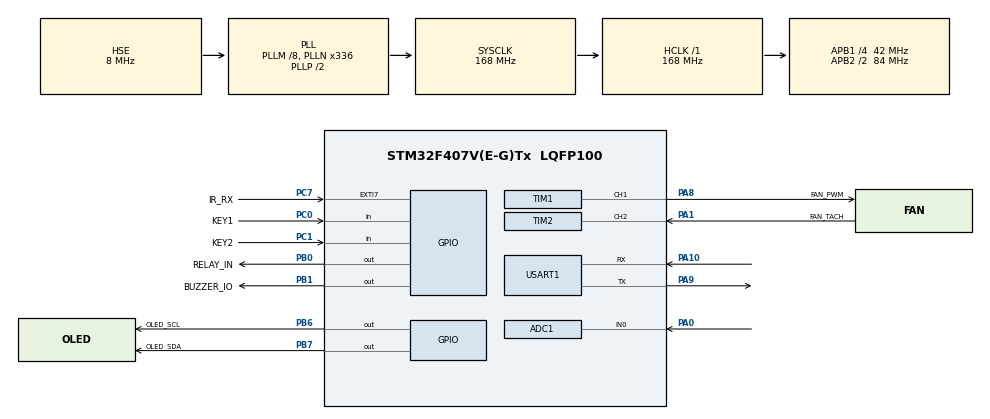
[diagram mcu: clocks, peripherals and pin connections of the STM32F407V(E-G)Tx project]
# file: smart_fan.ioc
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ADC1.Channel-0\#ChannelRegularConversion=ADC_CHANNEL_0
ADC1.NbrOfConversionFlag=1
ADC1.Rank-0\#ChannelRegularConversion=1
ADC1.SamplingTime-0\#ChannelRegularConversion=ADC_SAMPLETIME_480CYCLES
ADC1.master=1
Mcu.Family=STM32F4
Mcu.Name=STM32F407V(E-G)Tx
Mcu.Package=LQFP100
NVIC.EXTI9_5_IRQn=true\:4\:0\:false\:false\:true\:true\:true\:true
NVIC.PriorityGroup=NVIC_PRIORITYGROUP_4
NVIC.TIM2_IRQn=true\:3\:0\:false\:false\:true\:true\:true\:true
NVIC.USART1_IRQn=true\:2\:0\:false\:false\:true\:true\:true\:true
PA0-WKUP.Signal=ADCx_IN0
PA1.GPIO_Label=FAN_TACH
PA1.GPIO_PuPd=GPIO_PULLUP
PA1.GPIO_Speed=GPIO_SPEED_FREQ_LOW
PA1.Signal=S_TIM2_CH2
PA10.Mode=Asynchronous
PA10.Signal=USART1_RX
PA13.Signal=SYS_JTMS-SWDIO
PA14.Signal=SYS_JTCK-SWCLK
PA8.GPIO_Label=FAN_PWM
PA8.GPIO_ModeDefaultPP=GPIO_MODE_AF_OD
PA8.GPIO_PuPd=GPIO_NOPULL
PA8.GPIO_Speed=GPIO_SPEED_FREQ_LOW
PA8.Signal=S_TIM1_CH1
PA9.Mode=Asynchronous
PA9.Signal=USART1_TX
PB0.GPIO_Label=RELAY_IN
PB0.GPIO_ModeDefaultOutputPP=GPIO_MODE_OUTPUT_PP
PB0.GPIO_PuPd=GPIO_NOPULL
PB0.GPIO_Speed=GPIO_SPEED_FREQ_LOW
PB0.PinState=GPIO_PIN_RESET
PB0.Signal=GPIO_Output
PB1.GPIO_Label=BUZZER_IO
PB1.GPIO_ModeDefaultOutputPP=GPIO_MODE_OUTPUT_PP
PB1.GPIO_PuPd=GPIO_NOPULL
PB1.GPIO_Speed=GPIO_SPEED_FREQ_LOW
PB1.PinState=GPIO_PIN_SET
PB1.Signal=GPIO_Output
PB6.GPIO_Label=OLED_SCL
PB6.GPIO_ModeDefaultOutputPP=GPIO_MODE_OUTPUT_OD
PB6.GPIO_PuPd=GPIO_PULLUP
PB6.GPIO_Speed=GPIO_SPEED_FREQ_HIGH
PB6.Signal=GPIO_Output
PB7.GPIO_Label=OLED_SDA
PB7.GPIO_ModeDefaultOutputPP=GPIO_MODE_OUTPUT_OD
PB7.GPIO_PuPd=GPIO_PULLUP
PB7.GPIO_Speed=GPIO_SPEED_FREQ_HIGH
PB7.Signal=GPIO_Output
PC0.GPIO_Label=KEY1
PC0.GPIO_PuPd=GPIO_PULLUP
PC0.Signal=GPIO_Input
PC1.GPIO_Label=KEY2
PC1.GPIO_PuPd=GPIO_PULLUP
PC1.Signal=GPIO_Input
PC7.GPIO_Label=IR_RX
PC7.GPIO_ModeDefaultEXTI=GPIO_MODE_IT_RISING_FALLING
PC7.GPIO_PuPd=GPIO_PULLUP
PC7.Signal=GPXTI7
PH0-OSC_IN.Mode=HSE-External-Oscillator
PH0-OSC_IN.Signal=RCC_OSC_IN
PH1-OSC_OUT.Mode=HSE-External-Oscillator
PH1-OSC_OUT.Signal=RCC_OSC_OUT
ProjectManager.HeapSize=0x200
ProjectManager.StackSize=0x400
ProjectManager.TargetToolchain=CMake
RCC.48MHZClocksFreq_Value=48000000
RCC.AHBFreq_Value=168000000
RCC.APB1CLKDivider=RCC_HCLK_DIV4
RCC.APB1Freq_Value=42000000
RCC.APB1TimFreq_Value=84000000
RCC.APB2CLKDivider=RCC_HCLK_DIV2
RCC.APB2Freq_Value=84000000
RCC.APB2TimFreq_Value=168000000
RCC.CortexFreq_Value=168000000
RCC.HCLKFreq_Value=168000000
RCC.HSE_VALUE=8000000
RCC.HSI_VALUE=16000000
RCC.LSE_VALUE=32768
RCC.PLLM=8
RCC.PLLN=336
RCC.PLLQ=7
RCC.PLLSourceVirtual=RCC_PLLSOURCE_HSE
RCC.SYSCLKFreq_VALUE=168000000
RCC.SYSCLKSource=RCC_SYSCLKSOURCE_PLLCLK
RCC.VCOOutputFreq_Value=336000000
SH.ADCx_IN0.0=ADC1_IN0,IN0
SH.S_TIM1_CH1.0=TIM1_CH1,PWM Generation1 CH1
SH.S_TIM2_CH2.0=TIM2_CH2,Input_Capture2_from_TI2
TIM1.Channel-PWM\ Generation1\ CH1=TIM_CHANNEL_1
TIM1.Period=6719
TIM2.Channel-Input_Capture2_from_TI2=TIM_CHANNEL_2
TIM2.Prescaler=83
USART1.VirtualMode=VM_ASYNC
board=custom

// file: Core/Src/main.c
/* USER CODE BEGIN Header */
/**
  ******************************************************************************
  * @file           : main.c
  * @brief          : Main program body
  ******************************************************************************
  * @attention
  *
  * Copyright (c) 2026 STMicroelectronics.
  * All rights reserved.
  *
  * This software is licensed under terms that can be found in the LICENSE file
  * in the root directory of this software component.
  * If no LICENSE file comes with this software, it is provided AS-IS.
  *
  ******************************************************************************
  */
/* USER CODE END Header */
#include "main.h"

/* USER CODE BEGIN Includes */
#include "app/app_main.h"
/* USER CODE END Includes */

ADC_HandleTypeDef hadc1;

TIM_HandleTypeDef htim1;
TIM_HandleTypeDef htim2;

UART_HandleTypeDef huart1;

void SystemClock_Config(void);
static void MX_GPIO_Init(void);
static void MX_USART1_UART_Init(void);
static void MX_ADC1_Init(void);
static void MX_TIM1_Init(void);
static void MX_TIM2_Init(void);

int main(void)
{

  /* MCU Configuration--------------------------------------------------------*/

  /* Reset of all peripherals, Initializes the Flash interface and the Systick. */
  HAL_Init();

  /* Configure the system clock */
  SystemClock_Config();

  /* Initialize all configured peripherals */
  MX_GPIO_Init();
  MX_USART1_UART_Init();
  MX_ADC1_Init();
  MX_TIM1_Init();
  MX_TIM2_Init();
  /* USER CODE BEGIN 2 */
  if (app_main_init() != ERR_OK)
  {
    Error_Handler();
  }
  /* USER CODE END 2 */

  /* Infinite loop */
  /* USER CODE BEGIN WHILE */
  while (1)
  {
    app_main_run();   /* 正常情况不会返回 */
    /* USER CODE END WHILE */

  }
}

void SystemClock_Config(void)
{
  RCC_OscInitTypeDef RCC_OscInitStruct = {0};
  RCC_ClkInitTypeDef RCC_ClkInitStruct = {0};

  /** Configure the main internal regulator output voltage
  */
  __HAL_RCC_PWR_CLK_ENABLE();
  __HAL_PWR_VOLTAGESCALING_CONFIG(PWR_REGULATOR_VOLTAGE_SCALE1);

  /** Initializes the RCC Oscillators according to the specified parameters
  * in the RCC_OscInitTypeDef structure.
  */
  RCC_OscInitStruct.OscillatorType = RCC_OSCILLATORTYPE_HSE;
  RCC_OscInitStruct.HSEState = RCC_HSE_ON;
  RCC_OscInitStruct.PLL.PLLState = RCC_PLL_ON;
  RCC_OscInitStruct.PLL.PLLSource = RCC_PLLSOURCE_HSE;
  RCC_OscInitStruct.PLL.PLLM = 8;
  RCC_OscInitStruct.PLL.PLLN = 336;
  RCC_OscInitStruct.PLL.PLLP = RCC_PLLP_DIV2;
  RCC_OscInitStruct.PLL.PLLQ = 7;
  if (HAL_RCC_OscConfig(&RCC_OscInitStruct) != HAL_OK)
  {
    Error_Handler();
  }

  /** Initializes the CPU, AHB and APB buses clocks
  */
  RCC_ClkInitStruct.ClockType = RCC_CLOCKTYPE_HCLK|RCC_CLOCKTYPE_SYSCLK
                              |RCC_CLOCKTYPE_PCLK1|RCC_CLOCKTYPE_PCLK2;
  RCC_ClkInitStruct.SYSCLKSource = RCC_SYSCLKSOURCE_PLLCLK;
  RCC_ClkInitStruct.AHBCLKDivider = RCC_SYSCLK_DIV1;
  RCC_ClkInitStruct.APB1CLKDivider = RCC_HCLK_DIV4;
  RCC_ClkInitStruct.APB2CLKDivider = RCC_HCLK_DIV2;

  if (HAL_RCC_ClockConfig(&RCC_ClkInitStruct, FLASH_LATENCY_5) != HAL_OK)
  {
    Error_Handler();
  }
}

static void MX_ADC1_Init(void)
{

  ADC_ChannelConfTypeDef sConfig = {0};

  /** Configure the global features of the ADC (Clock, Resolution, Data Alignment and number of conversion)
  */
  hadc1.Instance = ADC1;
  hadc1.Init.ClockPrescaler = ADC_CLOCK_SYNC_PCLK_DIV4;
  hadc1.Init.Resolution = ADC_RESOLUTION_12B;
  hadc1.Init.ScanConvMode = DISABLE;
  hadc1.Init.ContinuousConvMode = DISABLE;
  hadc1.Init.DiscontinuousConvMode = DISABLE;
  hadc1.Init.ExternalTrigConvEdge = ADC_EXTERNALTRIGCONVEDGE_NONE;
  hadc1.Init.ExternalTrigConv = ADC_SOFTWARE_START;
  hadc1.Init.DataAlign = ADC_DATAALIGN_RIGHT;
  hadc1.Init.NbrOfConversion = 1;
  hadc1.Init.DMAContinuousRequests = DISABLE;
  hadc1.Init.EOCSelection = ADC_EOC_SINGLE_CONV;
  if (HAL_ADC_Init(&hadc1) != HAL_OK)
  {
    Error_Handler();
  }

  /** Configure for the selected ADC regular channel its corresponding rank in the sequencer and its sample time.
  */
  sConfig.Channel = ADC_CHANNEL_0;
  sConfig.Rank = 1;
  sConfig.SamplingTime = ADC_SAMPLETIME_480CYCLES;
  if (HAL_ADC_ConfigChannel(&hadc1, &sConfig) != HAL_OK)
  {
    Error_Handler();
  }

}

static void MX_TIM1_Init(void)
{

  TIM_MasterConfigTypeDef sMasterConfig = {0};
  TIM_OC_InitTypeDef sConfigOC = {0};
  TIM_BreakDeadTimeConfigTypeDef sBreakDeadTimeConfig = {0};

  htim1.Instance = TIM1;
  htim1.Init.Prescaler = 0;
  htim1.Init.CounterMode = TIM_COUNTERMODE_UP;
  htim1.Init.Period = 6719;
  htim1.Init.ClockDivision = TIM_CLOCKDIVISION_DIV1;
  htim1.Init.RepetitionCounter = 0;
  htim1.Init.AutoReloadPreload = TIM_AUTORELOAD_PRELOAD_DISABLE;
  if (HAL_TIM_PWM_Init(&htim1) != HAL_OK)
  {
    Error_Handler();
  }
  sMasterConfig.MasterOutputTrigger = TIM_TRGO_RESET;
  sMasterConfig.MasterSlaveMode = TIM_MASTERSLAVEMODE_DISABLE;
  if (HAL_TIMEx_MasterConfigSynchronization(&htim1, &sMasterConfig) != HAL_OK)
  {
    Error_Handler();
  }
  sConfigOC.OCMode = TIM_OCMODE_PWM1;
  sConfigOC.Pulse = 0;
  sConfigOC.OCPolarity = TIM_OCPOLARITY_HIGH;
  sConfigOC.OCNPolarity = TIM_OCNPOLARITY_HIGH;
  sConfigOC.OCFastMode = TIM_OCFAST_DISABLE;
  sConfigOC.OCIdleState = TIM_OCIDLESTATE_RESET;
  sConfigOC.OCNIdleState = TIM_OCNIDLESTATE_RESET;
  if (HAL_TIM_PWM_ConfigChannel(&htim1, &sConfigOC, TIM_CHANNEL_1) != HAL_OK)
  {
    Error_Handler();
  }
  sBreakDeadTimeConfig.OffStateRunMode = TIM_OSSR_DISABLE;
  sBreakDeadTimeConfig.OffStateIDLEMode = TIM_OSSI_DISABLE;
  sBreakDeadTimeConfig.LockLevel = TIM_LOCKLEVEL_OFF;
  sBreakDeadTimeConfig.DeadTime = 0;
  sBreakDeadTimeConfig.BreakState = TIM_BREAK_DISABLE;
  sBreakDeadTimeConfig.BreakPolarity = TIM_BREAKPOLARITY_HIGH;
  sBreakDeadTimeConfig.AutomaticOutput = TIM_AUTOMATICOUTPUT_DISABLE;
  if (HAL_TIMEx_ConfigBreakDeadTime(&htim1, &sBreakDeadTimeConfig) != HAL_OK)
  {
    Error_Handler();
  }
  HAL_TIM_MspPostInit(&htim1);

}

static void MX_TIM2_Init(void)
{

  TIM_MasterConfigTypeDef sMasterConfig = {0};
  TIM_IC_InitTypeDef sConfigIC = {0};

  htim2.Instance = TIM2;
  htim2.Init.Prescaler = 83;
  htim2.Init.CounterMode = TIM_COUNTERMODE_UP;
  htim2.Init.Period = 4294967295;
  htim2.Init.ClockDivision = TIM_CLOCKDIVISION_DIV1;
  htim2.Init.AutoReloadPreload = TIM_AUTORELOAD_PRELOAD_DISABLE;
  if (HAL_TIM_IC_Init(&htim2) != HAL_OK)
  {
    Error_Handler();
  }
  sMasterConfig.MasterOutputTrigger = TIM_TRGO_RESET;
  sMasterConfig.MasterSlaveMode = TIM_MASTERSLAVEMODE_DISABLE;
  if (HAL_TIMEx_MasterConfigSynchronization(&htim2, &sMasterConfig) != HAL_OK)
  {
    Error_Handler();
  }
  sConfigIC.ICPolarity = TIM_INPUTCHANNELPOLARITY_RISING;
  sConfigIC.ICSelection = TIM_ICSELECTION_DIRECTTI;
  sConfigIC.ICPrescaler = TIM_ICPSC_DIV1;
  sConfigIC.ICFilter = 0;
  if (HAL_TIM_IC_ConfigChannel(&htim2, &sConfigIC, TIM_CHANNEL_2) != HAL_OK)
  {
    Error_Handler();
  }

}

static void MX_USART1_UART_Init(void)
{

  huart1.Instance = USART1;
  huart1.Init.BaudRate = 115200;
  huart1.Init.WordLength = UART_WORDLENGTH_8B;
  huart1.Init.StopBits = UART_STOPBITS_1;
  huart1.Init.Parity = UART_PARITY_NONE;
  huart1.Init.Mode = UART_MODE_TX_RX;
  huart1.Init.HwFlowCtl = UART_HWCONTROL_NONE;
  huart1.Init.OverSampling = UART_OVERSAMPLING_16;
  if (HAL_UART_Init(&huart1) != HAL_OK)
  {
    Error_Handler();
  }

}

static void MX_GPIO_Init(void)
{
  GPIO_InitTypeDef GPIO_InitStruct = {0};

  /* GPIO Ports Clock Enable */
  __HAL_RCC_GPIOH_CLK_ENABLE();
  __HAL_RCC_GPIOC_CLK_ENABLE();
  __HAL_RCC_GPIOA_CLK_ENABLE();
  __HAL_RCC_GPIOB_CLK_ENABLE();

  /*Configure GPIO pin Output Level */
  HAL_GPIO_WritePin(GPIOB, RELAY_IN_Pin|OLED_SCL_Pin|OLED_SDA_Pin, GPIO_PIN_RESET);

  /*Configure GPIO pin Output Level */
  HAL_GPIO_WritePin(BUZZER_IO_GPIO_Port, BUZZER_IO_Pin, GPIO_PIN_SET);

  /*Configure GPIO pins : KEY1_Pin KEY2_Pin */
  GPIO_InitStruct.Pin = KEY1_Pin|KEY2_Pin;
  GPIO_InitStruct.Mode = GPIO_MODE_INPUT;
  GPIO_InitStruct.Pull = GPIO_PULLUP;
  HAL_GPIO_Init(GPIOC, &GPIO_InitStruct);

  /*Configure GPIO pins : RELAY_IN_Pin BUZZER_IO_Pin */
  GPIO_InitStruct.Pin = RELAY_IN_Pin|BUZZER_IO_Pin;
  GPIO_InitStruct.Mode = GPIO_MODE_OUTPUT_PP;
  GPIO_InitStruct.Pull = GPIO_NOPULL;
  GPIO_InitStruct.Speed = GPIO_SPEED_FREQ_LOW;
  HAL_GPIO_Init(GPIOB, &GPIO_InitStruct);

  /*Configure GPIO pin : IR_RX_Pin */
  GPIO_InitStruct.Pin = IR_RX_Pin;
  GPIO_InitStruct.Mode = GPIO_MODE_IT_RISING_FALLING;
  GPIO_InitStruct.Pull = GPIO_PULLUP;
  HAL_GPIO_Init(IR_RX_GPIO_Port, &GPIO_InitStruct);

  /*Configure GPIO pins : OLED_SCL_Pin OLED_SDA_Pin */
  GPIO_InitStruct.Pin = OLED_SCL_Pin|OLED_SDA_Pin;
  GPIO_InitStruct.Mode = GPIO_MODE_OUTPUT_OD;
  GPIO_InitStruct.Pull = GPIO_PULLUP;
  GPIO_InitStruct.Speed = GPIO_SPEED_FREQ_HIGH;
  HAL_GPIO_Init(GPIOB, &GPIO_InitStruct);

  /* EXTI interrupt init*/
  HAL_NVIC_SetPriority(EXTI9_5_IRQn, 4, 0);
  HAL_NVIC_EnableIRQ(EXTI9_5_IRQn);

}

void Error_Handler(void)
{
  __disable_irq();
  while (1)
  {
  }
}
